# ATSAMD21G17L register map
Vendor: Microchip Technology Inc.; Series: SAMD21; File version: G
CPU: CM0+ r0p1, little endian, no MPU, no FPU, VTOR, 2 interrupt priority bits, 30 interrupts
Registers are 32-bit, read-write, reset 0x0 unless marked. A register's access mark holds for its fields unless they carry their own. Offsets are from the block's base; [hi:lo] are bit positions; {n}, {i} and the like mark numbered series; 'fields as' and 'values as' point back to an identical list.

## EIC — External Interrupt Controller
Base 0x40001800; register names take the prefix EIC_
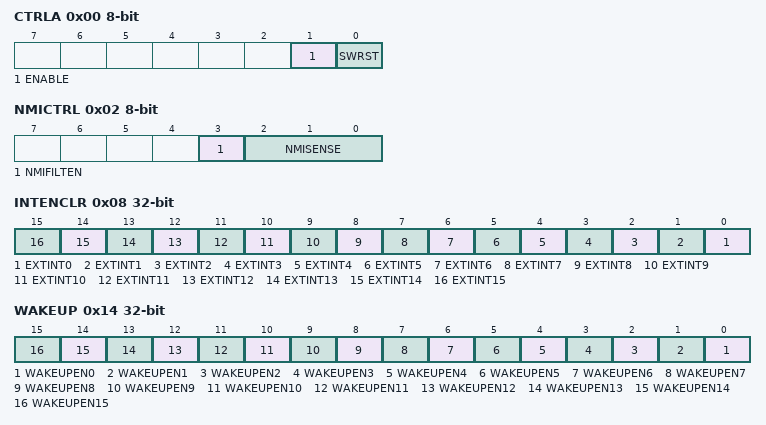
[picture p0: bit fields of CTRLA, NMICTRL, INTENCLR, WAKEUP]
0x00 CTRLA 8-bit — Control
  [1] ENABLE
  [0] SWRST — Software Reset
0x01 STATUS 8-bit ro
  [7] SYNCBUSY — Synchronization Busy
0x02 NMICTRL 8-bit — Non-Maskable Interrupt Control
  [3] NMIFILTEN — Non-Maskable Interrupt Filter Enable
  [2:0] NMISENSE — Non-Maskable Interrupt Sense
    0=NONE (No detection); 1=RISE (Rising-edge detection); 2=FALL (Falling-edge detection); 3=BOTH (Both-edges detection); 4=HIGH (High-level detection); 5=LOW (Low-level detection)
0x03 NMIFLAG 8-bit — Non-Maskable Interrupt Flag Status and Clear
  [0] NMI write-1-clears — Non-Maskable Interrupt
0x04 EVCTRL — Event Control
  [n] EXTINTEO{n} (n=0..15) — External Interrupt {n} Event Output Enable
  [15:0] EXTINTEO — External Interrupt Event Output Enable
0x08 INTENCLR — Interrupt Enable Clear
  [n] EXTINT{n} (n=0..15) — External Interrupt {n} Enable
0x0C INTENSET — Interrupt Enable Set
  [n] EXTINT{n} write-1-sets (n=0..15) — External Interrupt {n} Enable
  [15:0] EXTINT write-1-sets — External Interrupt Enable
0x10 INTFLAG — Interrupt Flag Status and Clear
  [n] EXTINT{n} write-1-clears (n=0..15) — External Interrupt {n}
  [15:0] EXTINT write-1-clears — External Interrupt Flag
0x14 WAKEUP — Wake-Up Enable
  [n] WAKEUPEN{n} (n=0..15) — External Interrupt {n} Wake-up Enable
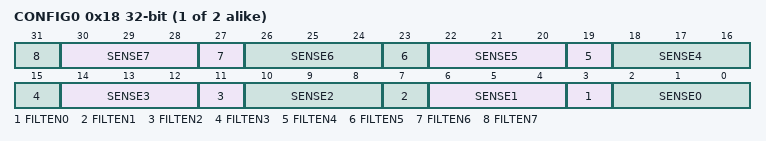
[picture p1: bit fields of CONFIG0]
{0x18+4i} CONFIG{i} (i=0..1) — Configuration n
  [4n+3] FILTEN{n} (n=0..7) — Filter {n} Enable
  [4n+2:4n] SENSE{n} (n=1..7) — Input Sense {n} Configuration
    0=NONE (No detection); 1=RISE (Rising edge detection); 2=FALL (Falling edge detection); 3=BOTH (Both edges detection); 4=HIGH (High level detection); 5=LOW (Low level detection)
  [2:0] SENSE0 — Input Sense 0 Configuration
    values as NMICTRL.NMISENSE

## GCLK — Generic Clock Generator
Base 0x40000C00; register names take the prefix GCLK_
0x00 CTRL 8-bit — Control
  [0] SWRST — Software Reset
0x01 STATUS 8-bit ro
  [7] SYNCBUSY — Synchronization Busy Status
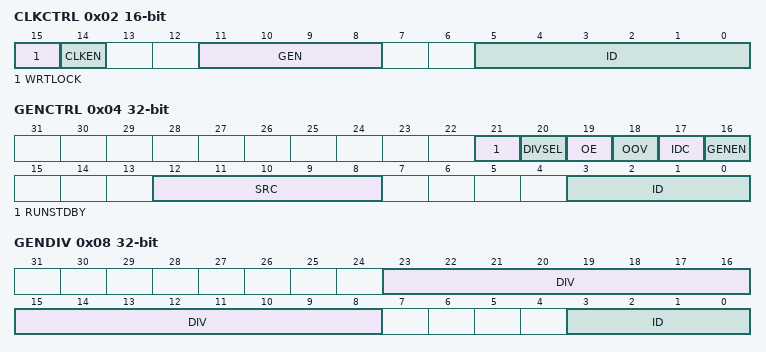
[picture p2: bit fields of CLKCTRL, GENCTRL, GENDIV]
0x02 CLKCTRL 16-bit — Generic Clock Control
  [15] WRTLOCK — Write Lock
  [14] CLKEN — Clock Enable
  [11:8] GEN — Generic Clock Generator
    {v}=GCLK{v} (Generic clock generator {v}) (v=0..7)
  [5:0] ID — Generic Clock Selection ID
    0=DFLL48; 1=FDPLL; 2=FDPLL32K; 3=WDT; 4=RTC; 5=EIC; {v}=EVSYS_{v-7} (v=7..18); 19=SERCOMX_SLOW; {v}=SERCOM{v-20}_CORE (v=20..25); 26=TCC0_TCC1; 27=TCC2_TC3; 28=TC4_TC5; 29=TC6_TC7; 30=ADC; 31=AC_DIG; 32=AC_ANA; 33=DAC; 37=TCC3
0x04 GENCTRL — Generic Clock Generator Control
  [21] RUNSTDBY — Run in Standby
  [20] DIVSEL — Divide Selection
    0=DIV1 (Divide input directly by divider factor); 1=DIV2 (Divide input by 2^(divider factor+ 1))
  [19] OE — Output Enable
  [18] OOV — Output Off Value
  [17] IDC — Improve Duty Cycle
  [16] GENEN — Generic Clock Generator Enable
  [12:8] SRC — Source Select
    0=XOSC (XOSC oscillator output); 1=GCLKIN (Generator input pad); 2=GCLKGEN1 (Generic clock generator 1 output); 3=OSCULP32K (OSCULP32K oscillator output); 4=OSC32K (OSC32K oscillator output); 5=XOSC32K (XOSC32K oscillator output); 6=OSC8M (OSC8M oscillator output); 7=DFLL48M (DFLL48M output); 8=FDPLL (FDPLL output)
  [3:0] ID — Generic Clock Generator Selection
0x08 GENDIV — Generic Clock Generator Division
  [23:8] DIV — Division Factor
  [3:0] ID — Generic Clock Generator Selection

## HMATRIX — HSB Matrix
Base 0x41007000; register names take the prefix HMATRIXB_
{0x80+8i} PRAS{i} (i=0..15) — Priority A for Slave
{0x84+8i} PRBS{i} (i=0..15) — Priority B for Slave
{0x110+4i} SFR{i} (i=0..15) — Special Function
  [31:0] SFR — Special Function Register
